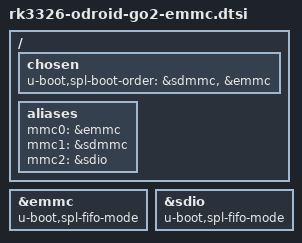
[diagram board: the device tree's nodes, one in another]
/* this should apply on top of rk3326-odroid-go2-u-boot.dtsi */
/ {
	chosen {
		u-boot,spl-boot-order = &sdmmc, &emmc;
	};

	aliases {
		mmc0 = &emmc;
		mmc1 = &sdmmc;
		mmc2 = &sdio;
	};
};

&emmc {
	bootph-all;

	/* mmc to sram can't do dma, prevent aborts transferring TF-A parts */
	u-boot,spl-fifo-mode;
	status = "okay";
};

&sdio {
	bootph-all;

	/* mmc to sram can't do dma, prevent aborts transferring TF-A parts */
	u-boot,spl-fifo-mode;
	status = "okay";
};
